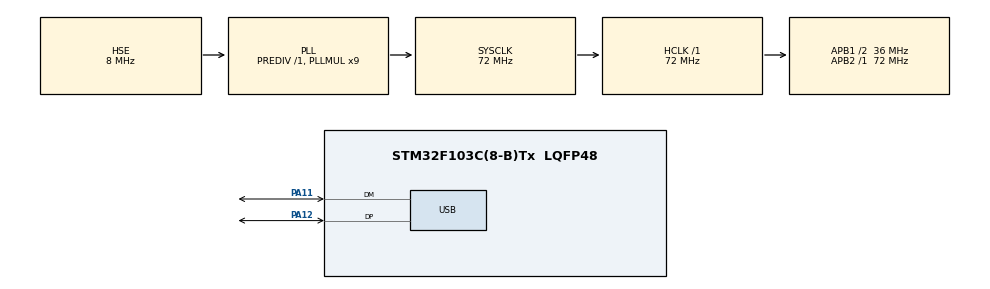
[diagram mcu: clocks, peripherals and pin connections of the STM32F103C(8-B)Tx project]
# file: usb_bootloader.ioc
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Mcu.Family=STM32F1
Mcu.Name=STM32F103C(8-B)Tx
Mcu.Package=LQFP48
NVIC.PriorityGroup=NVIC_PRIORITYGROUP_4
NVIC.USB_LP_CAN1_RX0_IRQn=true\:0\:0\:false\:false\:true\:false\:true\:true
PA11.Mode=Device
PA11.Signal=USB_DM
PA12.Mode=Device
PA12.Signal=USB_DP
PA13.Mode=Serial_Wire
PA13.Signal=SYS_JTMS-SWDIO
PA14.Mode=Serial_Wire
PA14.Signal=SYS_JTCK-SWCLK
PD0-OSC_IN.Mode=HSE-External-Oscillator
PD0-OSC_IN.Signal=RCC_OSC_IN
PD1-OSC_OUT.Mode=HSE-External-Oscillator
PD1-OSC_OUT.Signal=RCC_OSC_OUT
ProjectManager.HeapSize=0x200
ProjectManager.StackSize=0x400
ProjectManager.TargetToolchain=STM32CubeIDE
RCC.AHBFreq_Value=72000000
RCC.APB1CLKDivider=RCC_HCLK_DIV2
RCC.APB1Freq_Value=36000000
RCC.APB1TimFreq_Value=72000000
RCC.APB2Freq_Value=72000000
RCC.APB2TimFreq_Value=72000000
RCC.EnbaleCSS=true
RCC.HCLKFreq_Value=72000000
RCC.PLLMUL=RCC_PLL_MUL9
RCC.SYSCLKFreq_VALUE=72000000
RCC.SYSCLKSource=RCC_SYSCLKSOURCE_PLLCLK
RCC.USBFreq_Value=48000000
RCC.USBPrescaler=RCC_USBCLKSOURCE_PLL_DIV1_5
USB_DEVICE.CLASS_NAME_FS=MSC
USB_DEVICE.MSC_MEDIA_PACKET=1024
USB_DEVICE.VirtualMode=Msc
USB_DEVICE.VirtualModeFS=Msc_FS
VP_USB_DEVICE_VS_USB_DEVICE_MSC_FS.Mode=MSC_FS
board=custom

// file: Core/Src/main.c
/* USER CODE BEGIN Header */
/**
  ******************************************************************************
  * @file           : main.c
  * @brief          : Main program body
  ******************************************************************************
  * @attention
  *
  * Copyright (c) 2024 STMicroelectronics.
  * All rights reserved.
  *
  * This software is licensed under terms that can be found in the LICENSE file
  * in the root directory of this software component.
  * If no LICENSE file comes with this software, it is provided AS-IS.
  *
  ******************************************************************************
  */
/* USER CODE END Header */
#include "main.h"
#include "usb_device.h"

/* USER CODE BEGIN Includes */
#include "config.h"
/* USER CODE END Includes */

void SystemClock_Config(void);
static void MX_GPIO_Init(void);

/* USER CODE BEGIN 0 */
void Go_To_User_App(void)
{
  uint32_t app_jump_address;

  typedef void(*pFunction)(void); // Объявляем пользовательский тип
  pFunction Jump_To_Application; // И создаём переменную этого типа

  // Извлекаем адрес перехода из вектора Reset
  app_jump_address = *(uint32_t*) (STORAGE_ADDRESS + 4);
  // Приводим его к пользовательскому типу
  Jump_To_Application = (pFunction)app_jump_address;

  HAL_RCC_DeInit();
  HAL_DeInit();
  SysTick->CTRL = 0;
  SysTick->LOAD = 0;
  SysTick->VAL = 0;

  SCB->VTOR = STORAGE_ADDRESS;
  __set_MSP(*(__IO uint32_t*) STORAGE_ADDRESS); // Устанавливаем SP приложения
  Jump_To_Application(); // Запускаем приложение
}
/* USER CODE END 0 */

int main(void)
{

  /* MCU Configuration--------------------------------------------------------*/

  /* Reset of all peripherals, Initializes the Flash interface and the Systick. */
  HAL_Init();

  /* USER CODE BEGIN Init */
  // Включаем тактирование порта GPIOB
  __HAL_RCC_GPIOB_CLK_ENABLE();

  // Инициализируем вывод PB4, который подсоединён к +5v USB
  GPIO_InitTypeDef  GPIO_InitStruct;
  // Задаём конфигурацию для вывода PB4 как вход, с подтяжкой к земле
  GPIO_InitStruct.Pin = GPIO_PIN_4;
  GPIO_InitStruct.Mode = GPIO_MODE_INPUT;
  GPIO_InitStruct.Pull = GPIO_PULLDOWN;
  GPIO_InitStruct.Speed = GPIO_SPEED_FREQ_LOW;
  HAL_GPIO_Init(GPIOB, &GPIO_InitStruct);

  if( HAL_GPIO_ReadPin(GPIOB, GPIO_PIN_4) == GPIO_PIN_SET ) {
    // На выводе PB4 высокий уровень
    // Подготавливаем Mass Storage Device к загрузке прошивки
    /* USER CODE END Init */

    /* Configure the system clock */
    SystemClock_Config();

    /* Initialize all configured peripherals */
    MX_GPIO_Init();
    MX_USB_DEVICE_Init();

    /* Infinite loop */
    while (1)
    {

      /* USER CODE BEGIN 3 */
    }
  } else {
    // На выводе PB4 низкий уровень
    // Выполняем основную программу

    HAL_GPIO_DeInit(GPIOB, GPIO_PIN_4); // Сбрасываем PB4
    Go_To_User_App();
  }
  /* USER CODE END 3 */
}

void SystemClock_Config(void)
{
  RCC_OscInitTypeDef RCC_OscInitStruct = {0};
  RCC_ClkInitTypeDef RCC_ClkInitStruct = {0};
  RCC_PeriphCLKInitTypeDef PeriphClkInit = {0};

  /** Initializes the RCC Oscillators according to the specified parameters
  * in the RCC_OscInitTypeDef structure.
  */
  RCC_OscInitStruct.OscillatorType = RCC_OSCILLATORTYPE_HSE;
  RCC_OscInitStruct.HSEState = RCC_HSE_ON;
  RCC_OscInitStruct.HSEPredivValue = RCC_HSE_PREDIV_DIV1;
  RCC_OscInitStruct.HSIState = RCC_HSI_ON;
  RCC_OscInitStruct.PLL.PLLState = RCC_PLL_ON;
  RCC_OscInitStruct.PLL.PLLSource = RCC_PLLSOURCE_HSE;
  RCC_OscInitStruct.PLL.PLLMUL = RCC_PLL_MUL9;
  if (HAL_RCC_OscConfig(&RCC_OscInitStruct) != HAL_OK)
  {
    Error_Handler();
  }

  /** Initializes the CPU, AHB and APB buses clocks
  */
  RCC_ClkInitStruct.ClockType = RCC_CLOCKTYPE_HCLK|RCC_CLOCKTYPE_SYSCLK
                              |RCC_CLOCKTYPE_PCLK1|RCC_CLOCKTYPE_PCLK2;
  RCC_ClkInitStruct.SYSCLKSource = RCC_SYSCLKSOURCE_PLLCLK;
  RCC_ClkInitStruct.AHBCLKDivider = RCC_SYSCLK_DIV1;
  RCC_ClkInitStruct.APB1CLKDivider = RCC_HCLK_DIV2;
  RCC_ClkInitStruct.APB2CLKDivider = RCC_HCLK_DIV1;

  if (HAL_RCC_ClockConfig(&RCC_ClkInitStruct, FLASH_LATENCY_2) != HAL_OK)
  {
    Error_Handler();
  }
  PeriphClkInit.PeriphClockSelection = RCC_PERIPHCLK_USB;
  PeriphClkInit.UsbClockSelection = RCC_USBCLKSOURCE_PLL_DIV1_5;
  if (HAL_RCCEx_PeriphCLKConfig(&PeriphClkInit) != HAL_OK)
  {
    Error_Handler();
  }

  /** Enables the Clock Security System
  */
  HAL_RCC_EnableCSS();
}

static void MX_GPIO_Init(void)
{

  /* GPIO Ports Clock Enable */
  __HAL_RCC_GPIOD_CLK_ENABLE();
  __HAL_RCC_GPIOA_CLK_ENABLE();

}

void Error_Handler(void)
{
  __disable_irq();
  while (1)
  {
  }
}
